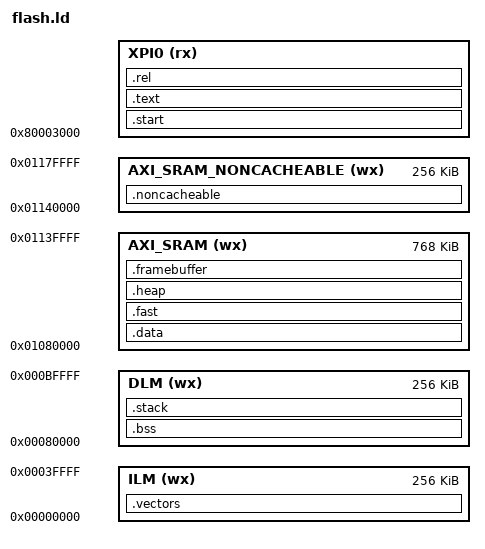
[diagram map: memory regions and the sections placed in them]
/*
 * Copyright 2021-2022 hpmicro
 * SPDX-License-Identifier: BSD-3-Clause
 */

ENTRY(_start)

STACK_SIZE = DEFINED(_stack_size) ? _stack_size : 0x4000;
HEAP_SIZE = DEFINED(_heap_size) ? _heap_size : 0x4000;

MEMORY
{
    XPI0 (rx) : ORIGIN = 0x80003000, LENGTH = _flash_size - 0x3000
    ILM (wx) : ORIGIN = 0, LENGTH = 256K
    DLM (wx) : ORIGIN = 0x80000, LENGTH = 256K
    AXI_SRAM (wx) : ORIGIN = 0x1080000, LENGTH = 768K
    AXI_SRAM_NONCACHEABLE (wx) : ORIGIN = 0x01140000, LENGTH = 256K
}

SECTIONS
{
    .start : {
        . = ALIGN(8);
        KEEP(*(.start))
    } > XPI0

    .text : {
        . = ALIGN(8);
        *(.text)
        *(.text*)
        *(.rodata)
        *(.rodata*)
        *(.srodata)
        *(.srodata*)

        *(.hash)
        *(.dyn*)
        *(.gnu*)
        *(.pl*)

        KEEP(*(.eh_frame))
        *(.eh_frame*)

        KEEP (*(.init))
        KEEP (*(.fini))
        . = ALIGN(8);
    } > XPI0

    .rel : {
        KEEP(*(.rel*))
    } > XPI0

    PROVIDE (__etext = .);
    PROVIDE (_etext = .);
    PROVIDE (etext = .);

    .vectors ORIGIN(ILM) : AT(etext) {
        . = ALIGN(8);
        __vector_ram_start__ = .;
        KEEP(*(.vector_table))
        KEEP(*(.isr_vector))
        . = ALIGN(8);
        __vector_ram_end__ = .;
    } > ILM

    .data : AT(etext + __vector_ram_end__ - __vector_ram_start__) {
        . = ALIGN(8);
        __data_start__ = .;
        __global_pointer$ = . + 0x800;
        *(.data)
        *(.data*)
        *(.sdata)
        *(.sdata*)
        *(.tdata)
        *(.tdata*)

        KEEP(*(.jcr))
        KEEP(*(.dynamic))
        KEEP(*(.got*))
        KEEP(*(.got))
        KEEP(*(.gcc_except_table))
        KEEP(*(.gcc_except_table.*))

        . = ALIGN(8);
        PROVIDE(__preinit_array_start = .);
        KEEP(*(.preinit_array))
        PROVIDE(__preinit_array_end = .);

        . = ALIGN(8);
        PROVIDE(__init_array_start = .);
        KEEP(*(SORT_BY_INIT_PRIORITY(.init_array.*)))
        KEEP(*(.init_array))
        PROVIDE(__init_array_end = .);

        . = ALIGN(8);
        PROVIDE(__finit_array_start = .);
        KEEP(*(SORT_BY_INIT_PRIORITY(.finit_array.*)))
        KEEP(*(.finit_array))
        PROVIDE(__finit_array_end = .);

        . = ALIGN(8);
        KEEP(*crtbegin*.o(.ctors))
        KEEP(*(EXCLUDE_FILE (*crtend*.o) .ctors))
        KEEP(*(SORT(.ctors.*)))
        KEEP(*(.ctors))

        . = ALIGN(8);
        KEEP(*crtbegin*.o(.dtors))
        KEEP(*(EXCLUDE_FILE (*crtend*.o) .dtors))
        KEEP(*(SORT(.dtors.*)))
        KEEP(*(.dtors))
        . = ALIGN(8);
        __data_end__ = .;
        PROVIDE (__edata = .);
        PROVIDE (_edata = .);
        PROVIDE (edata = .);
    } > AXI_SRAM

    .fast : AT(etext + __vector_ram_end__ - __vector_ram_start__ + __data_end__ - __data_start__) {
        . = ALIGN(8);
        __ramfunc_start__ = .;
        *(.fast)
        . = ALIGN(8);
        __ramfunc_end__ = .;
    } > AXI_SRAM

    .bss : {
        . = ALIGN(8);
        __bss_start__ = .;
        *(.bss)
        *(.bss*)
        *(.tbss*)
        *(.sbss*)
        *(.scommon)
        *(.scommon*)
        *(.tcommon*)
        *(.dynsbss*)
        *(COMMON)
        . = ALIGN(8);
        _end = .;
        __bss_end__ = .;
    } > DLM

    .heap : {
        . = ALIGN(8);
        __heap_start__ = .;
        . += HEAP_SIZE;
        __heap_end__ = .;
    } > AXI_SRAM

    .framebuffer (NOLOAD) : {
        . = ALIGN(8);
        KEEP(*(.framebuffer))
        . = ALIGN(8);
    } > AXI_SRAM

    .noncacheable : AT(etext + __vector_ram_end__ - __vector_ram_start__ + __data_end__ - __data_start__ + __ramfunc_end__ - __ramfunc_start__){
        . = ALIGN(8);
        __noncacheable_init_start__ = .;
        KEEP(*(.noncacheable.init))
        __noncacheable_init_end__ = .;
        KEEP(*(.noncacheable))
        __noncacheable_bss_start__ = .;
        KEEP(*(.noncacheable.bss))
        __noncacheable_bss_end__ = .;
        . = ALIGN(8);
    } > AXI_SRAM_NONCACHEABLE

    .stack : {
        . = ALIGN(8);
        __stack_base__ = .;
        . += STACK_SIZE;
        . = ALIGN(8);
        PROVIDE (_stack = .);
        PROVIDE (_stack_safe = .);
    } > DLM

    __noncacheable_start__ = ORIGIN(AXI_SRAM_NONCACHEABLE);
    __noncacheable_end__ = ORIGIN(AXI_SRAM_NONCACHEABLE) + LENGTH(AXI_SRAM_NONCACHEABLE);
}
